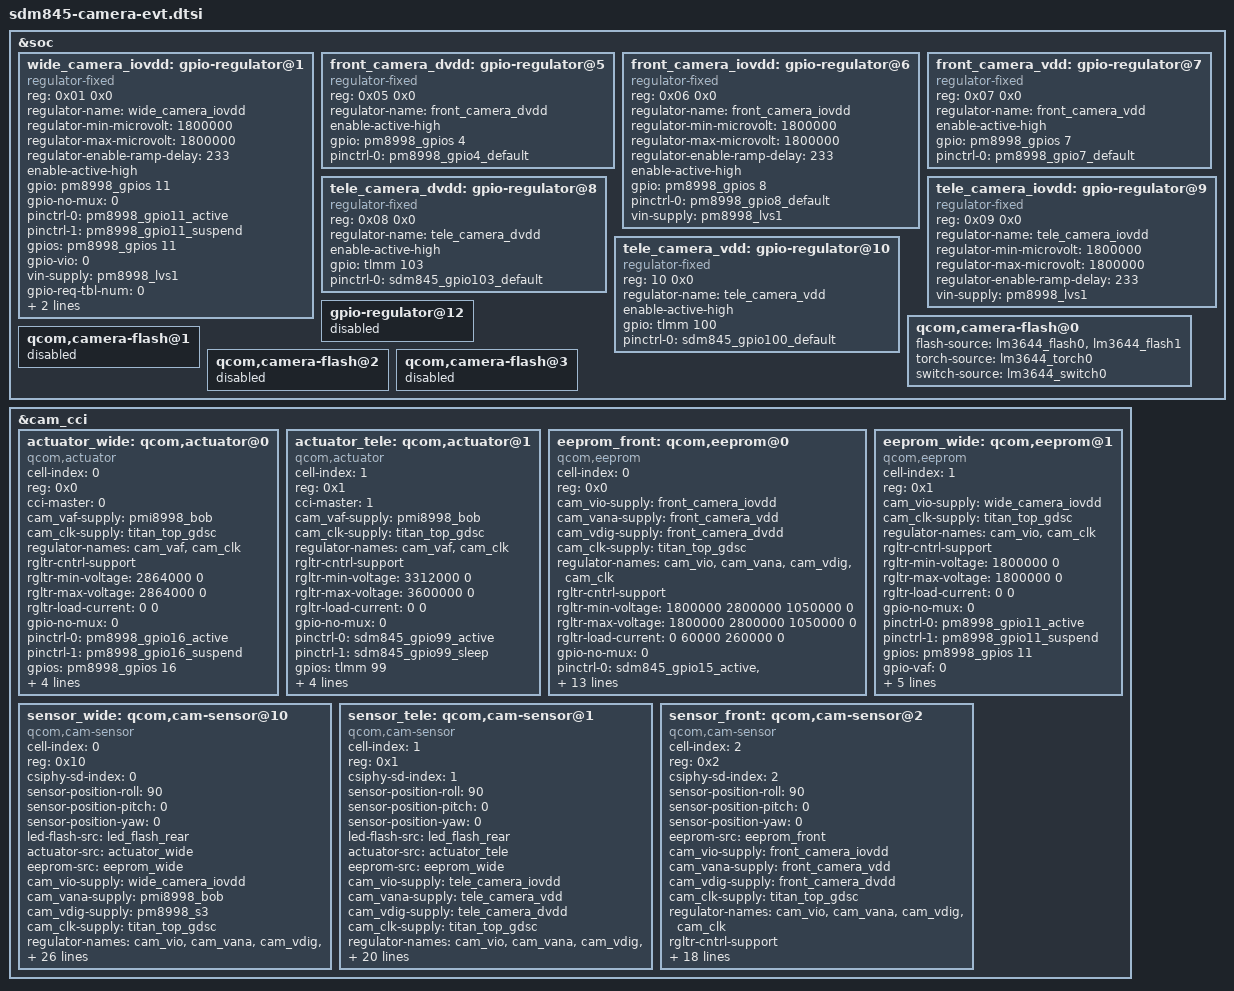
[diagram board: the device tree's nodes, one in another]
&soc {
/*
	wide_camera_dvdd: gpio-regulator@0 {
		compatible = "regulator-fixed";
		reg = <0x0 0x0>;
		regulator-name = "wide_camera_dvdd";
		enable-active-high;
		gpio = <&pm8998_gpios 10 0>;
		pinctrl-names = "default";
		pinctrl-0 = <&pm8998_gpio10_default>;
	};
*/
	wide_camera_iovdd: gpio-regulator@1 {
		compatible = "regulator-fixed";
		reg = <0x01 0x0>;
		regulator-name = "wide_camera_iovdd";
		regulator-min-microvolt = <1800000>;
		regulator-max-microvolt = <1800000>;
		regulator-enable-ramp-delay = <233>;
		enable-active-high;
		gpio = <&pm8998_gpios 11 0>;
		gpio-no-mux = <0>;
		pinctrl-names = "cam_default", "cam_suspend";
		pinctrl-0 = <&pm8998_gpio11_active>;
		pinctrl-1 = <&pm8998_gpio11_suspend>;
		gpios = <&pm8998_gpios 11 0>;
		gpio-vio = <0>;
		vin-supply = <&pm8998_lvs1>;

		gpio-req-tbl-num = <0>;
		gpio-req-tbl-flags = <1>;
		gpio-req-tbl-label = "CAM_VIO";

	};
/*
	wide_camera_vdd: gpio-regulator@2 {
		compatible = "regulator-fixed";
		reg = <0x02 0x0>;
		regulator-name = "wide_camera_vdd";
		enable-active-high;
		gpio = <&pm8998_gpios 12 0>;
		pinctrl-names = "default";
		pinctrl-0 = <&pm8998_gpio12_default>;
	};
	wide_camera_vcm: gpio-regulator@3 {
		compatible = "regulator-fixed";
		reg = <0x03 0x0>;
		regulator-name = "wide_camera_vcm";
		enable-active-high;
		gpio = <&pm8998_gpios 13 0>;
		pinctrl-names = "default";
		pinctrl-0 = <&pm8998_gpio13_default>;
	};

	wide_camera_ois: gpio-regulator@4 {
		compatible = "regulator-fixed";
		reg = <0x04 0x0>;
		regulator-name = "wide_camera_ois";
		enable-active-high;
		gpio = <&pm8998_gpios 9 0>;
		pinctrl-names = "default";
		pinctrl-0 = <&pm8998_gpio9_default>;
	};
*/
/*===========================================================*/
	front_camera_dvdd: gpio-regulator@5 {
		compatible = "regulator-fixed";
		reg = <0x05 0x0>;
		regulator-name = "front_camera_dvdd";
		enable-active-high;
		gpio = <&pm8998_gpios 4 0>;
		pinctrl-names = "default";
		pinctrl-0 = <&pm8998_gpio4_default>;
	};

	front_camera_iovdd: gpio-regulator@6 {
		compatible = "regulator-fixed";
		reg = <0x06 0x0>;
		regulator-name = "front_camera_iovdd";
		regulator-min-microvolt = <1800000>;
		regulator-max-microvolt = <1800000>;
		regulator-enable-ramp-delay = <233>;
		enable-active-high;
		gpio = <&pm8998_gpios 8 0>;
		pinctrl-names = "default";
		pinctrl-0 = <&pm8998_gpio8_default>;
		vin-supply = <&pm8998_lvs1>;
	};

	front_camera_vdd: gpio-regulator@7 {
		compatible = "regulator-fixed";
		reg = <0x07 0x0>;
		regulator-name = "front_camera_vdd";
		enable-active-high;
		gpio = <&pm8998_gpios 7 0>;
		pinctrl-names = "default";
		pinctrl-0 = <&pm8998_gpio7_default>;
	};

/*===========================================================*/
	tele_camera_dvdd: gpio-regulator@8 {
		compatible = "regulator-fixed";
		reg = <0x08 0x0>;
		regulator-name = "tele_camera_dvdd";
		enable-active-high;
		gpio = <&tlmm 103 0>;
		pinctrl-names = "default";
		pinctrl-0 = <&sdm845_gpio103_default>;
	};

	tele_camera_iovdd: gpio-regulator@9 {
		compatible = "regulator-fixed";
		reg = <0x09 0x0>;
		regulator-name = "tele_camera_iovdd";
		regulator-min-microvolt = <1800000>;
		regulator-max-microvolt = <1800000>;
		regulator-enable-ramp-delay = <233>;
//		enable-active-high;
//		gpio = <&tlmm 101 0>;
//		pinctrl-names = "default";
//		pinctrl-0 = <&sdm845_gpio101_default>;
		vin-supply = <&pm8998_lvs1>;
	};

	tele_camera_vdd: gpio-regulator@10 {
		compatible = "regulator-fixed";
		reg = <10 0x0>;
		regulator-name = "tele_camera_vdd";
		enable-active-high;
		gpio = <&tlmm 100 0>;
		pinctrl-names = "default";
		pinctrl-0 = <&sdm845_gpio100_default>;
	};
/*
	tele_camera_vcm: gpio-regulator@11 {
		compatible = "regulator-fixed";
		reg = <11 0x0>;
		regulator-name = "tele_camera_vcm";
		enable-active-high;
		gpio = <&tlmm 99 0>;
		pinctrl-names = "default";
		pinctrl-0 = <&sdm845_gpio99_default>;
	};
*/
	gpio-regulator@12 {
		status = "disabled";
	};
	qcom,camera-flash@0 {
		flash-source = <&lm3644_flash0 &lm3644_flash1>;
		torch-source = <&lm3644_torch0>;
		switch-source = <&lm3644_switch0>;
		status = "okay";
	};
	qcom,camera-flash@1 {
		status = "disabled";
	};
	qcom,camera-flash@2 {
		status = "disabled";
	};
	qcom,camera-flash@3 {
		status = "disabled";
	};
};

&cam_cci {
/*
	actuator_wide: qcom,actuator@0 {
		cell-index = <0>;
		reg = <0x0>;
		compatible = "qcom,actuator";
		cci-master = <0>;
		cam_vaf-supply = <&wide_camera_vcm>;
		regulator-names = "cam_vaf";
		rgltr-cntrl-support;
		rgltr-min-voltage = <2864000>;
		rgltr-max-voltage = <2864000>;
		rgltr-load-current = <0>;
	};
*/
	actuator_wide: qcom,actuator@0 {
		cell-index = <0>;
		reg = <0x0>;
		compatible = "qcom,actuator";
		cci-master = <0>;
		cam_vaf-supply = <&pmi8998_bob>;
		cam_clk-supply = <&titan_top_gdsc>;
		regulator-names = "cam_vaf", "cam_clk";
		rgltr-cntrl-support;
		rgltr-min-voltage = <2864000 0>;
		rgltr-max-voltage = <2864000 0>;
		rgltr-load-current = <0 0>;

		gpio-no-mux = <0>;
		pinctrl-names = "cam_default", "cam_suspend";
		pinctrl-0 = <&pm8998_gpio16_active>;
		pinctrl-1 = <&pm8998_gpio16_suspend>;
		gpios = <&pm8998_gpios 16 0>;
		gpio-vaf = <0>;

		gpio-req-tbl-num = <0>;
		gpio-req-tbl-flags = <1>;
		gpio-req-tbl-label = "CAM_VAF0";
		status = "ok";
	};

	actuator_tele: qcom,actuator@1 {
		cell-index = <1>;
		reg = <0x1>;
		compatible = "qcom,actuator";
		cci-master = <1>;
		cam_vaf-supply = <&pmi8998_bob>;
		cam_clk-supply = <&titan_top_gdsc>;
		regulator-names = "cam_vaf", "cam_clk";
		rgltr-cntrl-support;
		rgltr-min-voltage = <3312000 0>;
		rgltr-max-voltage = <3600000 0>;
		rgltr-load-current = <0 0>;

		gpio-no-mux = <0>;
		pinctrl-names = "cam_default", "cam_suspend";
		pinctrl-0 = <&sdm845_gpio99_active>;
		pinctrl-1 = <&sdm845_gpio99_sleep>;
		gpios = <&tlmm 99 0>;
		gpio-vaf = <0>;

		gpio-req-tbl-num = <0>;
		gpio-req-tbl-flags = <1>;
		gpio-req-tbl-label = "CAM_VAF1";
		status = "ok";
	};
/*
	ois_wide: qcom,ois@0 {
		cell-index = <0>;
		reg = <0x0>;
		compatible = "qcom,ois";
		cci-master = <0>;
		cam_vaf-supply = <&wide_camera_ois>;
		regulator-names = "cam_vaf";
		rgltr-cntrl-support;
		rgltr-min-voltage = <2864000>;
		rgltr-max-voltage = <2864000>;
		rgltr-load-current = <0>;
	};
*/
	eeprom_front: qcom,eeprom@0 {
		cell-index = <0>;
		compatible = "qcom,eeprom";
		reg = <0x0>;
		cam_vio-supply = <&front_camera_iovdd>;
		cam_vana-supply = <&front_camera_vdd>;
		cam_vdig-supply = <&front_camera_dvdd>;
		cam_clk-supply = <&titan_top_gdsc>;
		regulator-names = "cam_vio", "cam_vana", "cam_vdig", "cam_clk";
		rgltr-cntrl-support;
		rgltr-min-voltage = <1800000 2800000 1050000 0>;
		rgltr-max-voltage = <1800000 2800000 1050000 0>;
		rgltr-load-current = <0 60000 260000 0>;
		gpio-no-mux = <0>;
		pinctrl-names = "cam_default", "cam_suspend";
		pinctrl-0 = <&sdm845_gpio15_active
				 &sdm845_gpio9_active>;
		pinctrl-1 = <&sdm845_gpio15_sleep
				 &sdm845_gpio9_sleep>;
		gpios = <&tlmm 15 0>,
			<&tlmm 9 0>;
		gpio-reset = <1>;
		gpio-req-tbl-num = <0 1>;
		gpio-req-tbl-flags = <1 0>;
		gpio-req-tbl-label = "CAMIF_MCLK2",
					"CAM_RESET2";
		sensor-mode = <0>;
		cci-master = <1>;
		status = "ok";
		clocks = <&clock_camcc CAM_CC_MCLK2_CLK>;
		clock-names = "cam_clk";
		clock-cntl-level = "turbo";
		clock-rates = <24000000>;
	};

	eeprom_wide: qcom,eeprom@1 {
		cell-index = <1>;
		compatible = "qcom,eeprom";
		reg = <0x1>;
		cam_vio-supply = <&wide_camera_iovdd>;
		cam_clk-supply = <&titan_top_gdsc>;
		regulator-names = "cam_vio", "cam_clk";
		rgltr-cntrl-support;
		rgltr-min-voltage = <1800000 0>;
		rgltr-max-voltage = <1800000 0>;
		rgltr-load-current = <0 0>;

		gpio-no-mux = <0>;
		pinctrl-names = "cam_default", "cam_suspend";
		pinctrl-0 = <&pm8998_gpio11_active>;
		pinctrl-1 = <&pm8998_gpio11_suspend>;
		gpios = <&pm8998_gpios 11 0>;
		gpio-vaf = <0>;

		gpio-req-tbl-num = <0>;
		gpio-req-tbl-flags = <1>;
		gpio-req-tbl-label = "CAM_VIO";
		vin-supply = <&pm8998_lvs1>;

		cci-master = <0>;
		status = "ok";
	};

	sensor_wide: qcom,cam-sensor@10 {
		cell-index = <0>;
		compatible = "qcom,cam-sensor";
		reg = <0x10>;
		csiphy-sd-index = <0>;
		sensor-position-roll = <90>;
		sensor-position-pitch = <0>;
		sensor-position-yaw = <0>;
		led-flash-src = <&led_flash_rear>;
		actuator-src = <&actuator_wide>;
		eeprom-src = <&eeprom_wide>;
//		ois-src = <&ois_wide>;
		cam_vio-supply = <&wide_camera_iovdd>;
/*		cam_vana-supply = <&wide_camera_vdd>; */
		cam_vana-supply = <&pmi8998_bob>;
/*		cam_vdig-supply = <&wide_camera_dvdd>; */
		cam_vdig-supply = <&pm8998_s3>;

		cam_clk-supply = <&titan_top_gdsc>;
		regulator-names = "cam_vio", "cam_vana", "cam_vdig", "cam_clk";
		rgltr-cntrl-support;
		rgltr-min-voltage = <1800000 3312000 1352000 0>;
		rgltr-max-voltage = <1800000 3600000 1352000 0>;
		rgltr-load-current = <0 60000 260000 0>;
		gpio-no-mux = <0>;
		pinctrl-names = "cam_default", "cam_suspend";
		pinctrl-0 = <&sdm845_gpio13_active &sdm845_gpio80_active &pm8998_gpio10_active &pm8998_gpio12_active>;
		pinctrl-1 = <&sdm845_gpio13_sleep &sdm845_gpio80_sleep &pm8998_gpio10_suspend &pm8998_gpio12_suspend>;
		gpios = <&tlmm 13 0>,
			<&tlmm 80 0>,
			<&pm8998_gpios 10 0>,
			<&pm8998_gpios 12 0>;
		gpio-reset = <1>;
		gpio-vdig = <2>;
		gpio-vana = <3>;
		gpio-req-tbl-num = <0 1 2 3>;
		gpio-req-tbl-flags = <1 0 0 0>;
		gpio-req-tbl-label = "CAMIF_MCLK0",
					"CAM_RESET0",
					"CAM_VDIG0",
					"CAM_VANA0";
		sensor-mode = <0>;
		cci-master = <0>;
		status = "ok";
		clocks = <&clock_camcc CAM_CC_MCLK0_CLK>;
		clock-names = "cam_clk";
		clock-cntl-level = "turbo";
		clock-rates = <24000000>;
	};
	sensor_tele: qcom,cam-sensor@1 {
		cell-index = <1>;
		compatible = "qcom,cam-sensor";
		reg = <0x1>;
		csiphy-sd-index = <1>;
		sensor-position-roll = <90>;
		sensor-position-pitch = <0>;
		sensor-position-yaw = <0>;
		led-flash-src = <&led_flash_rear>;
		actuator-src = <&actuator_tele>;
		eeprom-src = <&eeprom_wide>;
		cam_vio-supply = <&tele_camera_iovdd>;
//		cam_vio-supply = <&wide_camera_iovdd>;
		cam_vana-supply = <&tele_camera_vdd>; 
		cam_vdig-supply = <&tele_camera_dvdd>; 

		cam_clk-supply = <&titan_top_gdsc>;
		regulator-names = "cam_vio", "cam_vana", "cam_vdig", "cam_clk";
		rgltr-cntrl-support;
		rgltr-min-voltage = <1800000 2850000 1052000 0>;
		rgltr-max-voltage = <1800000 2850000 1052000 0>;
		rgltr-load-current = <0 60000 260000 0>;
		gpio-no-mux = <0>;
		pinctrl-names = "cam_default", "cam_suspend";
		pinctrl-0 = <&sdm845_gpio14_active &sdm845_gpio30_active>;
		pinctrl-1 = <&sdm845_gpio14_sleep &sdm845_gpio30_sleep>;
		gpios = <&tlmm 14 0>,
			<&tlmm 30 0>;
//			<&tlmm 101 0>;
		gpio-reset = <1>;
//		gpio-vio = <2>;
		gpio-req-tbl-num = <0 1>;
		gpio-req-tbl-flags = <1 0>;
		gpio-req-tbl-label = "CAMIF_MCLK1",
					"CAM_RESET1";
//					"CAM_VIO1";
		sensor-mode = <0>;
		cci-master = <1>;
		status = "ok";
		clocks = <&clock_camcc CAM_CC_MCLK1_CLK>;
		clock-names = "cam_clk";
		clock-cntl-level = "turbo";
		clock-rates = <24000000>;
	};

	sensor_front: qcom,cam-sensor@2 {
		cell-index = <2>;
		compatible = "qcom,cam-sensor";
		reg = <0x2>;
		csiphy-sd-index = <2>;
		sensor-position-roll = <90>;
		sensor-position-pitch = <0>;
		sensor-position-yaw = <0>;
		eeprom-src = <&eeprom_front>;
		cam_vio-supply = <&front_camera_iovdd>;
		cam_vana-supply = <&front_camera_vdd>;
		cam_vdig-supply = <&front_camera_dvdd>;
		cam_clk-supply = <&titan_top_gdsc>;
		regulator-names = "cam_vio", "cam_vana", "cam_vdig", "cam_clk";
		rgltr-cntrl-support;
		rgltr-min-voltage = <1800000 2800000 1050000 0>;
		rgltr-max-voltage = <1800000 2800000 1050000 0>;
		rgltr-load-current = <0 60000 260000 0>;
		gpio-no-mux = <0>;
		pinctrl-names = "cam_default", "cam_suspend";
		pinctrl-0 = <&sdm845_gpio15_active
				 &sdm845_gpio9_active>;
		pinctrl-1 = <&sdm845_gpio15_sleep
				 &sdm845_gpio9_sleep>;
		gpios = <&tlmm 15 0>,
			<&tlmm 9 0>;
		gpio-reset = <1>;
		gpio-req-tbl-num = <0 1>;
		gpio-req-tbl-flags = <1 0>;
		gpio-req-tbl-label = "CAMIF_MCLK2",
					"CAM_RESET2";
		sensor-mode = <0>;
		cci-master = <1>;
		status = "ok";
		clocks = <&clock_camcc CAM_CC_MCLK2_CLK>;
		clock-names = "cam_clk";
		clock-cntl-level = "turbo";
		clock-rates = <24000000>;
	};
};
